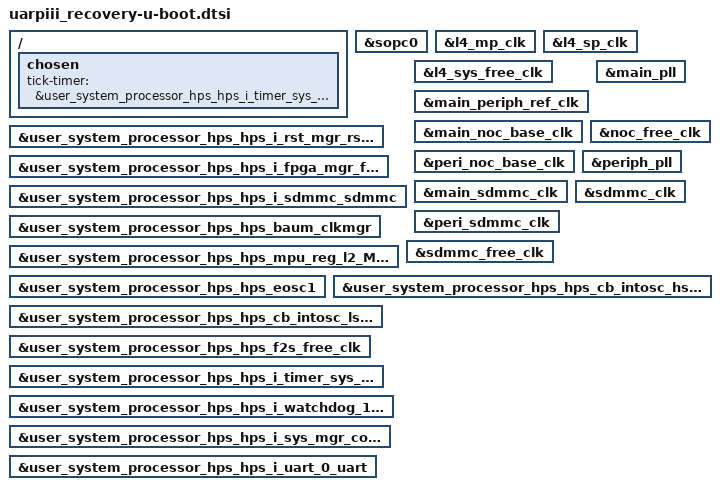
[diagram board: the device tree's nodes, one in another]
/*
 * This is an additional DTS include file which is used only when
 * building the U-Boot/SPL portion. It allows modifying the full
 * DTS file generated by sopc2dts to set parameters specific to the
 * bootloader stage.
 *
 * The overrides in this file are manually assigned, with names which
 * must match those generated in the main DTS file. This should be the
 * case as long as the HPS location in the FPGA design files is never
 * changed.
 */

#include "uarpiii_recovery.h"

#include "socfpga_arria10-handoff.dtsi"
#include "socfpga_arria10_handoff_u-boot.dtsi"

/ {
	chosen {
		tick-timer = &user_system_processor_hps_hps_i_timer_sys_0_timer;
		bootph-all;
	};
};

// Main SOC group from our DTS
&sopc0 {
    bootph-all;
};

&user_system_processor_hps_hps_i_rst_mgr_rstmgr {
	bootph-all;
};

&user_system_processor_hps_hps_i_fpga_mgr_fpgamgrregs {
	bootph-all;
};

&user_system_processor_hps_hps_i_sdmmc_sdmmc {
    bootph-all;
};

&user_system_processor_hps_hps_baum_clkmgr {
    bootph-all;
};

&user_system_processor_hps_hps_mpu_reg_l2_MPUL2 {
	bootph-all;
};

&l4_mp_clk {
	bootph-all;
};

&l4_sp_clk {
	bootph-all;
};

&l4_sys_free_clk {
	bootph-all;
};

&main_periph_ref_clk {
	bootph-all;
};

&main_pll {
	bootph-all;
};

&main_noc_base_clk {
	bootph-all;
};

&noc_free_clk {
	bootph-all;
};

&peri_noc_base_clk {
	bootph-all;
};

&periph_pll {
	bootph-all;
};

&main_sdmmc_clk {
	bootph-all;
};

&peri_sdmmc_clk {
	bootph-all;
};

&sdmmc_free_clk {
	bootph-all;
};

&sdmmc_clk {
	bootph-all;
};

&user_system_processor_hps_hps_eosc1 {
	bootph-all;
};

&user_system_processor_hps_hps_cb_intosc_hs_div2_clk {
	bootph-all;
};

&user_system_processor_hps_hps_cb_intosc_ls_clk {
	bootph-all;
};

&user_system_processor_hps_hps_f2s_free_clk {
	bootph-all;
};
  
&user_system_processor_hps_hps_i_timer_sys_0_timer {
	bootph-all;
};

&user_system_processor_hps_hps_i_watchdog_1_l4wd {
	bootph-all;
};

&user_system_processor_hps_hps_i_sys_mgr_core {
    bootph-all;
};

&user_system_processor_hps_hps_i_uart_0_uart {
    bootph-all;
};

